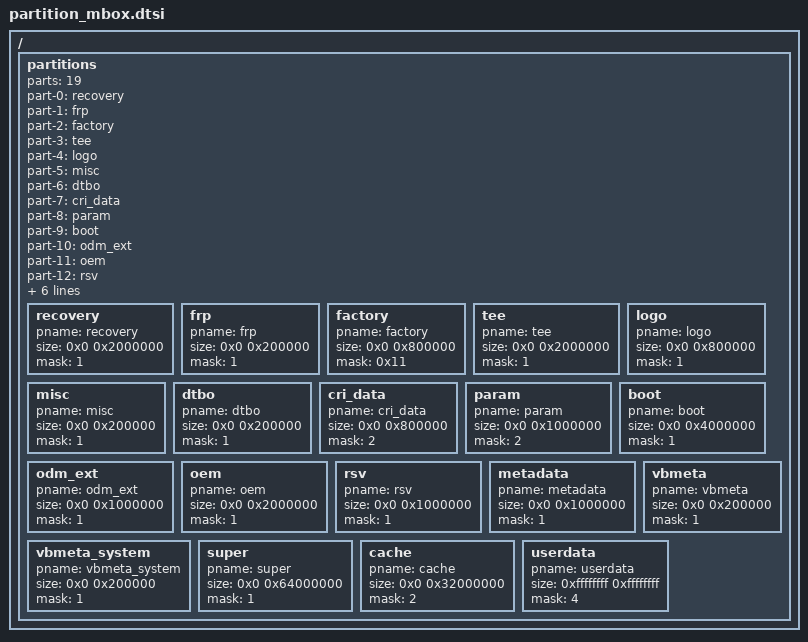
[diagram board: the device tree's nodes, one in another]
/*
 * Amlogic partition set for normal
 *
 * Copyright (c) 2017-2017 Amlogic Ltd
 *
 * This file is licensed under a dual GPLv2 or BSD license.
 *
 */

#include "firmware.dtsi"

/ {
    partitions: partitions{
		parts = <19>;
		part-0 = <&recovery>;
		part-1 = <&frp>;
		part-2 = <&factory>;
		part-3 = <&tee>;
		part-4 = <&logo>;
		part-5 = <&misc>;
		part-6 = <&dtbo>;
		part-7 = <&cri_data>;
		part-8 = <&param>;
		part-9 = <&boot>;
		part-10 = <&odm_ext>;
		part-11 = <&oem>;
		part-12 = <&rsv>;
		part-13 = <&metadata>;
		part-14 = <&vbmeta>;
		part-15 = <&vbmeta_system>;
		part-16 = <&super>;
		part-17 = <&cache>;
		part-18 = <&userdata>;

		recovery:recovery{
			pname = "recovery";
			size = <0x0 0x2000000>;
			mask = <1>;
		};
		frp:frp{
			pname = "frp";
			size = <0x0 0x200000>;
			mask = <1>;
		};
		factory:factory{
			pname = "factory";
			size = <0x0 0x800000>;
			mask = <0x11>;
		};
		tee:tee{
			pname = "tee";
			size = <0x0 0x2000000>;
			mask = <1>;
		};
		logo:logo{
			pname = "logo";
			size = <0x0 0x800000>;
			mask = <1>;
		};
		misc:misc{
			pname = "misc";
			size = <0x0 0x200000>;
			mask = <1>;
		};
		dtbo:dtbo{
			pname = "dtbo";
			size = <0x0 0x200000>;
			mask = <1>;
		};
		cri_data:cri_data
		{
			pname = "cri_data";
			size = <0x0 0x800000>;
			mask = <2>;
		};
		param:param{
			pname = "param";
			size = <0x0 0x1000000>;
			mask = <2>;
		};
		boot:boot
		{
			pname = "boot";
			size = <0x0 0x4000000>;
			mask = <1>;
		};
		odm_ext:odm_ext
		{
			pname = "odm_ext";
			size = <0x0 0x1000000>;
			mask = <1>;
		};
		oem:oem
		{
			pname = "oem";
			size = <0x0 0x2000000>;
			mask = <1>;
		};
		rsv:rsv{
			pname = "rsv";
			size = <0x0 0x1000000>;
			mask = <1>;
		};
		metadata:metadata{
			pname = "metadata";
			size = <0x0 0x1000000>;
			mask = <1>;
		};
		vbmeta:vbmeta{
			pname = "vbmeta";
			size = <0x0 0x200000>;
			mask = <1>;
		};
		vbmeta_system:vbmeta_system{
			pname = "vbmeta_system";
			size = <0x0 0x200000>;
			mask = <1>;
		};
		super:super
		{
			pname = "super";
			size = <0x0 0x64000000>;
			mask = <1>;
		};
		cache:cache
		{
			pname = "cache";
			size = <0x0 0x32000000>;
			mask = <2>;
		};
		userdata:userdata
		{
			pname = "userdata";
			size = <0xffffffff 0xffffffff>;
			mask = <4>;
		};
	};
};/* end of / */
